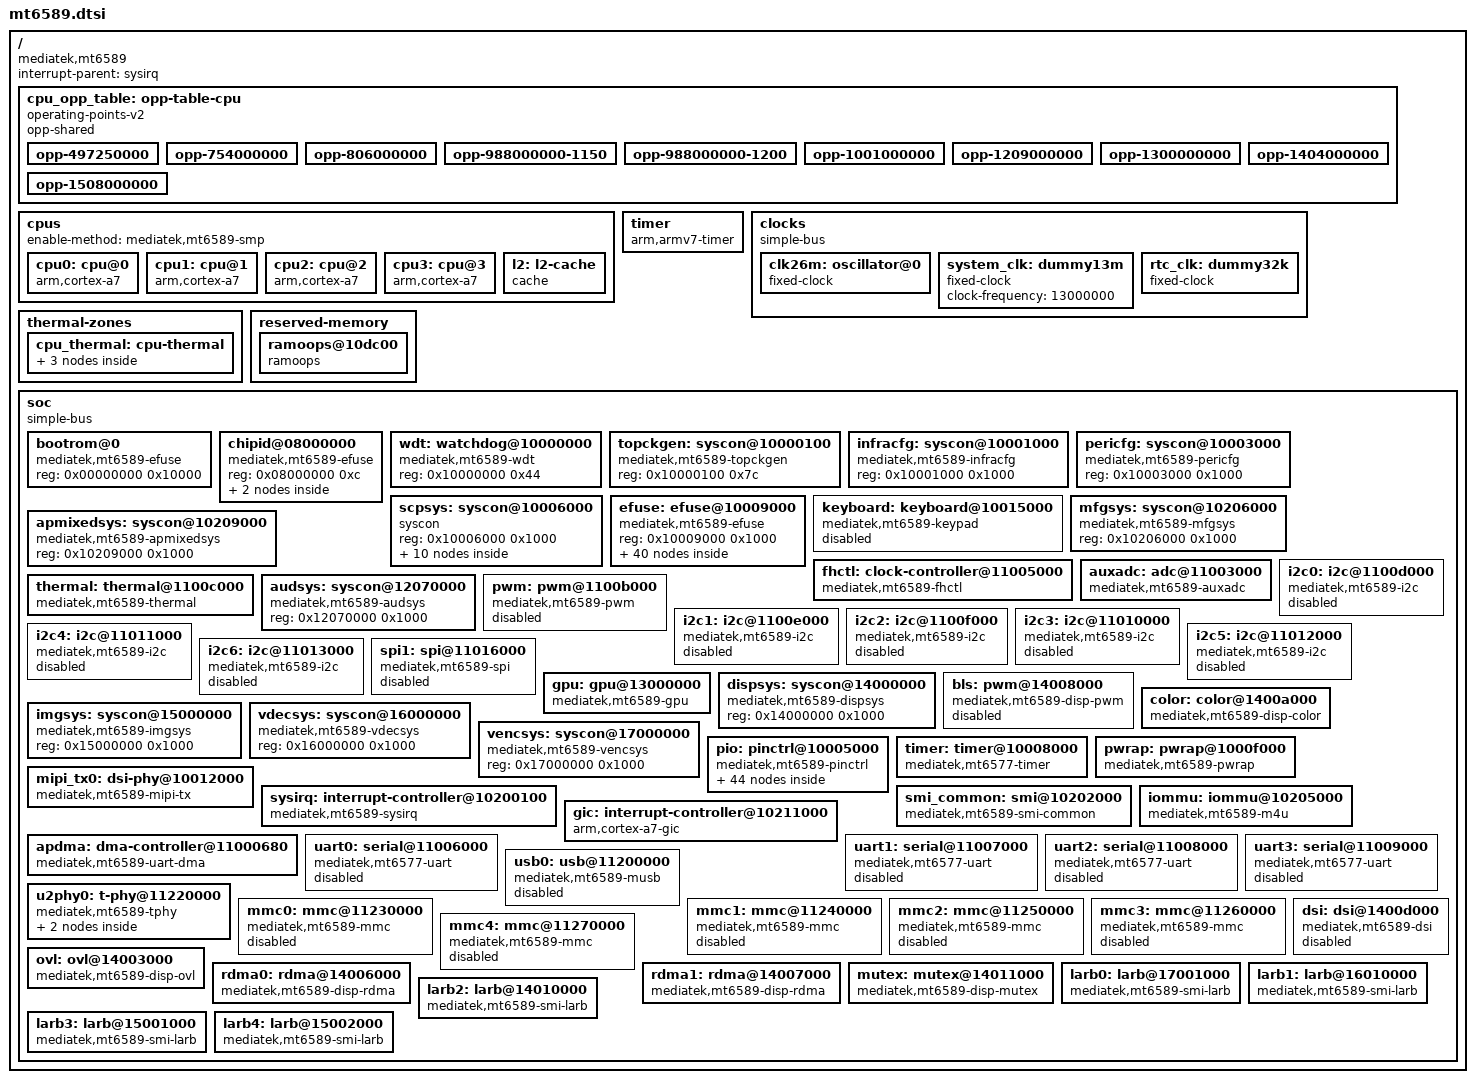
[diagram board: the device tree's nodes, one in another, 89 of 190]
// SPDX-License-Identifier: GPL-2.0+
/*
 * Copyright (c) 2014 MundoReader S.L.
 * Author: Matthias Brugger <matthias.bgg@gmail.com>
 *
*/

#include <dt-bindings/interrupt-controller/irq.h>
#include <dt-bindings/interrupt-controller/arm-gic.h>
#include <dt-bindings/clock/mediatek,mt6589-clk.h>
#include <dt-bindings/phy/phy.h>
#include <dt-bindings/reset/mt6589-resets.h>
#include <dt-bindings/pinctrl/mt6589-pinfunc.h>
#include <dt-bindings/memory/mt6589-larb-port.h>
#include <dt-bindings/power/mt6589-power.h>
#include <dt-bindings/thermal/thermal.h>

/ {
	#address-cells = <1>;
	#size-cells = <1>;
	compatible = "mediatek,mt6589";
	interrupt-parent = <&sysirq>;

	cpu_opp_table: opp-table-cpu {
		compatible = "operating-points-v2";
		opp-shared;

		/*
		 * CONFIG_MTK_FORCE_CPU_89T : 1.5 GHz : PTP 3
		 * bit 0 : free mode : ptp_free_grade
		 * bit 1 : 1.5 GHz : PTP 3 : mt6589_freqs_e1_2
		 * bit 2 : 1.4 GHz : PTP 2 : mt6589_freqs_e1_3
		 * bit 3 : 1.3 GHz : PTP 1 : mt6589_freqs_e1_4
		 * bit 4 : 1.2 GHz : PTP 0 : mt6589_freqs_e1
		 * bit 5 : 1.1 GHz : PTP 8 : mt6589_freqs_e1 (fallback)
		 * bit 6 : 1.0 GHz : PTP 9 : mt6589_freqs_e1_5
		 * bit 7 : 1.0 GHz : PTP 10: mt6589_freqs_e1 (fallback)
		 * ----- : ------- : PTP 4 : mt6589_freqs_e1_1
		 * ----- : ------- : PTP 5 : mt6589_freqs_e1_0
		 ** preloader
		 * 6, 7  : 806 MHz
		 * other : 1001MHz
		 */

		opp-497250000 {
			opp-hz = /bits/ 64 <497250000>;
			opp-microvolt = <950000>;
			opp-supported-hw = <0xff>; /* bits 0-7 */
		};

		opp-754000000 {
			opp-hz = /bits/ 64 <754000000>;
			opp-microvolt = <1050000>;
			opp-supported-hw = <0xff>;
		};

		/* TODO: can bit 6 hw run this freq with 1.15 V ? */
		opp-806000000 {
			opp-hz = /bits/ 64 <806000000>;
			opp-microvolt = <1150000>;
			opp-supported-hw = <0xff>;
		};

		opp-988000000-1150 {
			opp-hz = /bits/ 64 <988000000>;
			opp-microvolt = <1150000>;
			opp-supported-hw = <0xbf>; /* bits 0-5,7 */
		};

		opp-988000000-1200 {
			opp-hz = /bits/ 64 <988000000>;
			opp-microvolt = <1200000>;
			opp-supported-hw = <0x40>; /* bit 6 */
		};

		opp-1001000000 {
			opp-hz = /bits/ 64 <1001000000>;
			opp-microvolt = <1150000>;
			opp-supported-hw = <0x3f>; /* bits 0-5 */
		};

		opp-1209000000 {
			opp-hz = /bits/ 64 <1209000000>;
			opp-microvolt = <1200000>;
			opp-supported-hw = <0xbf>;
		};

		opp-1300000000 {
			opp-hz = /bits/ 64 <1300000000>;
			opp-microvolt = <1250000>;
			opp-supported-hw = <0x0f>; /* bits 0-3 */
		};

		opp-1404000000 {
			opp-hz = /bits/ 64 <1404000000>;
			opp-microvolt = <1250000>;
			opp-supported-hw = <0x07>; /* bits 0-2 */
		};

		opp-1508000000 {
			opp-hz = /bits/ 64 <1508000000>;
			opp-microvolt = <1250000>;
			opp-supported-hw = <0x03>; /* bits 0-1 */
		};

		/*
		 * TODO: check devinfo[10][6:4] (ptp-free@120)
		 */
		// opp-1599000000 {
		// 	opp-hz = /bits/ 64 <1599000000>;
		// 	opp-microvolt = <1250000>;
		// 	opp-supported-hw = <0x01>; /* bit 0 */
		// };

		// opp-1703000000 {
		// 	opp-hz = /bits/ 64 <1703000000>;
		// 	opp-microvolt = <1250000>;
		// 	opp-supported-hw = <0x01>; /* bit 0 */
		// };
	};

	cpus: cpus {
		#address-cells = <1>;
		#size-cells = <0>;
		enable-method = "mediatek,mt6589-smp";

		cpu0: cpu@0 {
			device_type = "cpu";
			compatible = "arm,cortex-a7";
			reg = <0x0>;

			i-cache-size = <32768>;
			i-cache-line-size = <32>;
			i-cache-sets = <512>;
			d-cache-size = <32768>;
			d-cache-line-size = <64>;
			d-cache-sets = <128>;
			next-level-cache = <&l2>;

			clocks = <&infracfg CLK_INFRA_MUX1>,
				 <&clk26m>;
			clock-names = "cpu", "intermediate";
			operating-points-v2 = <&cpu_opp_table>;
			nvmem-cells = <&chip_grade>;
			nvmem-cell-names = "speed_grade";
		};
		cpu1: cpu@1 {
			device_type = "cpu";
			compatible = "arm,cortex-a7";
			reg = <0x1>;

			i-cache-size = <32768>;
			i-cache-line-size = <32>;
			i-cache-sets = <512>;
			d-cache-size = <32768>;
			d-cache-line-size = <64>;
			d-cache-sets = <128>;
			next-level-cache = <&l2>;

			clocks = <&infracfg CLK_INFRA_MUX1>,
				 <&clk26m>;
			clock-names = "cpu", "intermediate";
			operating-points-v2 = <&cpu_opp_table>;
			nvmem-cells = <&chip_grade>;
			nvmem-cell-names = "speed_grade";
		};
		cpu2: cpu@2 {
			device_type = "cpu";
			compatible = "arm,cortex-a7";
			reg = <0x2>;

			i-cache-size = <32768>;
			i-cache-line-size = <32>;
			i-cache-sets = <512>;
			d-cache-size = <32768>;
			d-cache-line-size = <64>;
			d-cache-sets = <128>;
			next-level-cache = <&l2>;

			clocks = <&infracfg CLK_INFRA_MUX1>,
				 <&clk26m>;
			clock-names = "cpu", "intermediate";
			operating-points-v2 = <&cpu_opp_table>;
			nvmem-cells = <&chip_grade>;
			nvmem-cell-names = "speed_grade";
		};
		cpu3: cpu@3 {
			device_type = "cpu";
			compatible = "arm,cortex-a7";
			reg = <0x3>;

			i-cache-size = <32768>;
			i-cache-line-size = <32>;
			i-cache-sets = <512>;
			d-cache-size = <32768>;
			d-cache-line-size = <64>;
			d-cache-sets = <128>;
			next-level-cache = <&l2>;

			clocks = <&infracfg CLK_INFRA_MUX1>,
				 <&clk26m>;
			clock-names = "cpu", "intermediate";
			operating-points-v2 = <&cpu_opp_table>;
			nvmem-cells = <&chip_grade>;
			nvmem-cell-names = "speed_grade";
		};

		l2: l2-cache {
			compatible = "cache";
			cache-level = <2>;
			cache-size = <0x100000>;
			cache-line-size = <64>;
			cache-sets = <2048>;
			cache-unified;
		};
	};

	timer {
		compatible = "arm,armv7-timer";
		interrupt-parent = <&gic>;
		interrupts = <GIC_PPI 13 (GIC_CPU_MASK_SIMPLE(4) | IRQ_TYPE_LEVEL_LOW)>,
			     <GIC_PPI 14 (GIC_CPU_MASK_SIMPLE(4) | IRQ_TYPE_LEVEL_LOW)>,
			     <GIC_PPI 11 (GIC_CPU_MASK_SIMPLE(4) | IRQ_TYPE_LEVEL_LOW)>,
			     <GIC_PPI 10 (GIC_CPU_MASK_SIMPLE(4) | IRQ_TYPE_LEVEL_LOW)>;
		clock-frequency = <13000000>;
		arm,cpu-registers-not-fw-configured;
	};

	clocks {
		#address-cells = <1>;
		#size-cells = <1>;
		compatible = "simple-bus";
		ranges;

		clk26m: oscillator@0 {
			compatible = "fixed-clock";
			#clock-cells = <0>;
			clock-frequency = <26000000>;
			clock-output-names = "clk26m";
		};

		system_clk: dummy13m {
			compatible = "fixed-clock";
			clock-frequency = <13000000>;
			#clock-cells = <0>;
		};

		rtc_clk: dummy32k {
			compatible = "fixed-clock";
			clock-frequency = <32000>;
			clock-output-names = "rtc_clk";
			#clock-cells = <0>;
		};
	};

	thermal-zones {
		cpu_thermal: cpu-thermal {
			polling-delay-passive = <1000>;
			polling-delay = <1000>;

			thermal-sensors = <&thermal 0>;

			trips {
				cpu_alert: cpu-alert {
					temperature = <85000>;
					hysteresis = <2000>;
					type = "hot";
				};

				cpu_crit: cpu-crit {
					temperature = <115000>;
					hysteresis = <2000>;
					type = "critical";
				};
			};
		};
	};

	reserved-memory {
		#address-cells = <1>;
		#size-cells = <1>;
		ranges;

		/* part of on-chip sram */
		ramoops@10dc00 {
			compatible = "ramoops";
			reg = <0x0010dc00 0x1c00>;
			record-size = <0x400>;
			console-size = <0x1000>;
		};
	};

	soc {
		#address-cells = <1>;
		#size-cells = <1>;
		compatible = "simple-bus";
		ranges;

		bootrom@0 {
			compatible = "mediatek,mt6589-efuse",
				     "mediatek,mt6572-efuse";
			reg = <0x00000000 0x10000>;
			#address-cells = <1>;
			#size-cells = <1>;
		};

		/*
		 * 0x08000000  CHIP_ID   0x8a006583  Main(0x6583) / Sub(0x8a00)
		 * 0x08000004  CHIP_VER  0x0000ca00  HW ID(0xca00) / SW ID(0x0000)
		 */
		chipid@08000000 {
			compatible = "mediatek,mt6589-efuse",
				     "mediatek,mt6572-efuse";
			reg = <0x08000000 0xc>;
			#address-cells = <1>;
			#size-cells = <1>;

			chip-id@0 {
				reg = <0x0 0x4>;
			};

			chip-ver@ {
				reg = <0x4 0x4>;
			};
		};

		wdt: watchdog@10000000 {
			compatible = "mediatek,mt6589-wdt";
			reg = <0x10000000 0x44>;
			#reset-cells = <1>;
		};

		topckgen: syscon@10000100 {
			compatible = "mediatek,mt6589-topckgen", "syscon";
			reg = <0x10000100 0x7c>;
			#clock-cells = <1>;
		};

		infracfg: syscon@10001000 {
			compatible = "mediatek,mt6589-infracfg", "syscon";
			reg = <0x10001000 0x1000>;
			#clock-cells = <1>;
			#reset-cells = <1>;
		};

		pericfg: syscon@10003000 {
			compatible = "mediatek,mt6589-pericfg", "syscon";
			reg = <0x10003000 0x1000>;
			#clock-cells = <1>;
			#reset-cells = <1>;
		};

		scpsys: syscon@10006000 {
			compatible = "syscon", "simple-mfd";
			reg = <0x10006000 0x1000>;
			#power-domain-cells = <1>;

			spm: power-controller {
				compatible = "mediatek,mt6589-power-controller";
				#address-cells = <1>;
				#size-cells = <0>;
				#power-domain-cells = <1>;

				power-domain@MT6589_POWER_DOMAIN_MD1 {
					reg = <MT6589_POWER_DOMAIN_MD1>;
					#power-domain-cells = <0>;
					mediatek,infracfg = <&infracfg>;
				};

				power-domain@MT6589_POWER_DOMAIN_MD2 {
					reg = <MT6589_POWER_DOMAIN_MD2>;
					#power-domain-cells = <0>;
					mediatek,infracfg = <&infracfg>;
				};

				power-domain@MT6589_POWER_DOMAIN_DPY {
					reg = <MT6589_POWER_DOMAIN_DPY>;
					#power-domain-cells = <0>;
				};

				power-domain@MT6589_POWER_DOMAIN_DIS {
					reg = <MT6589_POWER_DOMAIN_DIS>;
					clocks = <&topckgen CLK_TOP_MUX_DISP>;
					clock-names = "disp";
					#power-domain-cells = <0>;
				};

				power-domain@MT6589_POWER_DOMAIN_MFG {
					reg = <MT6589_POWER_DOMAIN_MFG>;
					clocks = <&topckgen CLK_TOP_MUX_MFG>,
						 <&topckgen CLK_TOP_MUX_SMI_MFG_AS>;
					clock-names = "mfg", "mfg_as";
					#power-domain-cells = <0>;
					mediatek,infracfg = <&infracfg>;
				};

				power-domain@MT6589_POWER_DOMAIN_ISP {
					reg = <MT6589_POWER_DOMAIN_ISP>;
					#power-domain-cells = <0>;
				};

				power-domain@MT6589_POWER_DOMAIN_IFR {
					reg = <MT6589_POWER_DOMAIN_IFR>;
					#power-domain-cells = <0>;
				};

				power-domain@MT6589_POWER_DOMAIN_VEN {
					reg = <MT6589_POWER_DOMAIN_VEN>;
					clocks = <&topckgen CLK_TOP_MUX_VENC>;
					clock-names = "venc";
					#power-domain-cells = <0>;
				};

				power-domain@MT6589_POWER_DOMAIN_VDE {
					reg = <MT6589_POWER_DOMAIN_VDE>;
					clocks = <&topckgen CLK_TOP_MUX_VDEC>;
					clock-names = "vdec";
					#power-domain-cells = <0>;
				};
			};
		};

		efuse: efuse@10009000 {
			compatible = "mediatek,mt6589-efuse",
				     "mediatek,mt6572-efuse";
			reg = <0x10009000 0x1000>;
			#address-cells = <1>;
			#size-cells = <1>;

			cell@20 {
				reg = <0x20 0x4>;
			};

			cell@30 {
				reg = <0x30 0x4>;
			};

			cell@38 {
				reg = <0x38 0x4>;
			};

			/*
			 * bit[2:0]  chip_grade
			 *
			 * bit[27:24]  core_count_flag
			 *   0x0   : 4 cores
			 *   others: 2 cores
			 */
			chip_grade: chip-grade@40 {
				reg = <0x40 0x4>;
				bits = <0 3>;
			};

			core_count_flag: core-count@40 {
				reg = <0x40 0x4>;
				bits = <24 4>;
			};

			cell@40 {
				reg = <0x40 0x4>;
			};

			cell@44 {
				reg = <0x44 0x4>;
			};

			cell@48 {
				reg = <0x48 0x4>;
			};

			/*
			 * Secure boot flag
			 *   bit[1]  sbc_enabled  Secure Boot Check
			 *   bit[2]  daa_enabled  Device Authentication Auth
			 *   bit[3]  sla_enabled  Secure Lock Auth
			 */
			sbc_enabled: sbc@60 {
				reg = <0x60 0x4>;
				bits = <1 1>;
			};

			daa_enabled: daa@60 {
				reg = <0x60 0x4>;
				bits = <2 1>;
			};

			sla_enabled: sla@60 {
				reg = <0x60 0x4>;
				bits = <3 1>;
			};

			thermal_cal_data: thermal-cal@100 {
				reg = <0x100 0xc>;
			};

			dis_3g: dis-3g@100 {
				reg = <0x100 0x4>;
				bits = <24 1>;
			};

			ptp_free_grade: ptp-free@120 {
				reg = <0x120 0x4>;
				bits = <4 3>;
			};

			cell@120 {
				reg = <0x120 0x4>;
			};

			cell@130 {
				reg = <0x130 0x4>;
			};

			usb_serial_lo: usb-serial-lo@140 {
				reg = <0x140 0x4>;
			};

			usb_serial_hi: usb-serial-hi@144 {
				reg = <0x144 0x4>;
			};

			/*
			 * bit[15:13]  RG_USB20_TERM_VREF_SEL offset (3bit)
			 * bit[12:10]  RG_USB20_CLKREF_REF offset (3bit)
			 * bit[9:7]    RG_USB20_VRT_VREF_SEL offset (3bit)
			 */
			usb_term_vref: usb-term-vref@170 {
				reg = <0x170 0x2>;
				bits = <7 3>;
			};

			usb_clkref: usb-clkref@170 {
				reg = <0x170 0x2>;
				bits = <10 3>;
			};

			usb_vrt_vref: usb-vrt-vref@170 {
				reg = <0x170 0x2>;
				bits = <13 3>;
			};

			cell@170 {
				reg = <0x170 0x4>;
			};

			cell@174 {
				reg = <0x174 0x4>;
			};

			ptp_od_data: ptp-od@178 {
				reg = <0x178 0x10>;
			};

			ptp_initen: ptp-initen@178 {
				reg = <0x178 0x4>;
				bits = <0 1>;
			};

			ptp_monen: ptp-monen@178 {
				reg = <0x178 0x4>;
				bits = <1 1>;
			};

			ptp_mdes: ptp-mdes@178 {
				reg = <0x178 0x4>;
				bits = <8 8>;
			};

			ptp_bdes: ptp-bdes@178 {
				reg = <0x178 0x4>;
				bits = <16 8>;
			};

			ptp_dcmdet: ptp-dcmdet@178 {
				reg = <0x178 0x4>;
				bits = <24 8>;
			};

			ptp_dcconfig: ptp-dcconfig@17c {
				reg = <0x17c 0x4>;
				bits = <0 24>;
			};

			ptp_dcbdet: ptp-dcbdet@17c {
				reg = <0x17c 0x4>;
				bits = <24 8>;
			};

			ptp_ageconfig: ptp-ageconfig@180 {
				reg = <0x180 0x4>;
				bits = <0 24>;
			};

			ptp_agem: ptp-agem@180 {
				reg = <0x180 0x4>;
				bits = <24 8>;
			};

			ptp_dvtfixed: ptp-dvtfixed@184 {
				reg = <0x184 0x4>;
				bits = <8 8>;
			};

			ptp_mtdes: ptp-mtdes@184 {
				reg = <0x184 0x4>;
				bits = <16 8>;
			};

			ptp_vco: ptp-vco@184 {
				reg = <0x184 0x4>;
				bits = <24 8>;
			};

			cell@178 {
				reg = <0x178 0x4>;
			};

			cell@17c {
				reg = <0x17c 0x4>;
			};

			cell@180 {
				reg = <0x180 0x4>;
			};

			cell@184 {
				reg = <0x184 0x4>;
			};
		};

		keyboard: keyboard@10015000 {
			compatible = "mediatek,mt6589-keypad",
				     "mediatek,mt6779-keypad";
			reg = <0x10015000 0x1000>;
			interrupts = <GIC_SPI 129 IRQ_TYPE_EDGE_FALLING>;
			clocks = <&infracfg CLK_INFRA_KP>;
			clock-names = "kpd";
			status = "disabled";
		};

		mfgsys: syscon@10206000 {
			compatible = "mediatek,mt6589-mfgsys", "syscon";
			reg = <0x10206000 0x1000>;
			#clock-cells = <1>;
		};

		apmixedsys: syscon@10209000 {
			compatible = "mediatek,mt6589-apmixedsys", "syscon";
			reg = <0x10209000 0x1000>;
			#clock-cells = <1>;
		};

		fhctl: clock-controller@11005000 {
			compatible = "mediatek,mt6589-fhctl";
			reg = <0x11005000 0x100>;
			clocks = <&apmixedsys CLK_APMIXED_ARMPLL>,
				 <&apmixedsys CLK_APMIXED_MAINPLL>,
				 <&apmixedsys CLK_APMIXED_MSDCPLL>,
				 <&apmixedsys CLK_APMIXED_TVDPLL>,
				 <&apmixedsys CLK_APMIXED_LVDSPLL>;
			mediatek,hopping-ssc-percent = <0>, <0>, <3>, <0>, <0>;
		};

		auxadc: adc@11003000 {
			compatible = "mediatek,mt6589-auxadc";
			reg = <0x11003000 0x1000>;
			clocks = <&pericfg CLK_PERI1_AUXADC>;
			clock-names = "main";
			#io-channel-cells = <1>;
		};

		thermal: thermal@1100c000 {
			compatible = "mediatek,mt6589-thermal";
			reg = <0x1100c000 0x1000>;
			interrupts = <GIC_SPI 38 IRQ_TYPE_LEVEL_LOW>;
			clocks = <&pericfg CLK_PERI0_THERM>,
				 <&pericfg CLK_PERI1_AUXADC>;
			clock-names = "therm", "auxadc";
			mediatek,auxadc = <&auxadc>;
			mediatek,apmixedsys = <&apmixedsys>;
			nvmem-cells = <&thermal_cal_data>;
			nvmem-cell-names = "calibration-data";
			#thermal-sensor-cells = <1>;
		};

		audsys: syscon@12070000 {
			compatible = "mediatek,mt6589-audsys", "syscon";
			reg = <0x12070000 0x1000>;
			#clock-cells = <1>;
		};

		pwm: pwm@1100b000 {
			compatible = "mediatek,mt6589-pwm",
				     "mediatek,mt6795-pwm";
			reg = <0x1100b000 0x1000>;
			#pwm-cells = <2>;
			interrupts = <GIC_SPI 37 IRQ_TYPE_LEVEL_LOW>;
			clocks = <&pericfg CLK_PERI0_PWM>,
				 <&pericfg CLK_PERI0_PWM>,
				 <&pericfg CLK_PERI0_PWM1>,
				 <&pericfg CLK_PERI0_PWM2>,
				 <&pericfg CLK_PERI0_PWM3>,
				 <&pericfg CLK_PERI0_PWM4>,
				 <&pericfg CLK_PERI0_PWM5>,
				 <&pericfg CLK_PERI0_PWM6>,
				 <&pericfg CLK_PERI0_PWM7>;
			clock-names = "top", "main", "pwm1", "pwm2", "pwm3",
				      "pwm4", "pwm5", "pwm6", "pwm7";
			status = "disabled";
		};

		i2c0: i2c@1100d000 {
			compatible = "mediatek,mt6589-i2c";
			reg = <0x1100d000 0x1000>,
			      <0x11000300 0x80>;
			interrupts = <GIC_SPI 44 IRQ_TYPE_LEVEL_LOW>;
			clocks = <&pericfg CLK_PERI0_I2C0>,
				 <&pericfg CLK_PERI0_APDMA>;
			clock-names = "main", "dma";
			clock-div = <16>;
			status = "disabled";
			#address-cells = <1>;
			#size-cells = <0>;
		};

		i2c1: i2c@1100e000 {
			compatible = "mediatek,mt6589-i2c";
			reg = <0x1100e000 0x1000>,
			      <0x11000380 0x80>;
			interrupts = <GIC_SPI 45 IRQ_TYPE_LEVEL_LOW>;
			clocks = <&pericfg CLK_PERI0_I2C1>,
				 <&pericfg CLK_PERI0_APDMA>;
			clock-names = "main", "dma";
			clock-div = <16>;
			status = "disabled";
			#address-cells = <1>;
			#size-cells = <0>;
		};

		i2c2: i2c@1100f000 {
			compatible = "mediatek,mt6589-i2c";
			reg = <0x1100f000 0x1000>,
			      <0x11000400 0x80>;
			interrupts = <GIC_SPI 46 IRQ_TYPE_LEVEL_LOW>;
			clocks = <&pericfg CLK_PERI0_I2C2>,
				 <&pericfg CLK_PERI0_APDMA>;
			clock-names = "main", "dma";
			clock-div = <16>;
			status = "disabled";
			#address-cells = <1>;
			#size-cells = <0>;
		};

		i2c3: i2c@11010000 {
			compatible = "mediatek,mt6589-i2c";
			reg = <0x11010000 0x1000>,
			      <0x11000480 0x80>;
			interrupts = <GIC_SPI 47 IRQ_TYPE_LEVEL_LOW>;
			clocks = <&pericfg CLK_PERI0_I2C3>,
				 <&pericfg CLK_PERI0_APDMA>;
			clock-names = "main", "dma";
			clock-div = <16>;
			status = "disabled";
			#address-cells = <1>;
			#size-cells = <0>;
		};

		i2c4: i2c@11011000 {
			compatible = "mediatek,mt6589-i2c";
			reg = <0x11011000 0x1000>,
			      <0x11000500 0x80>;
			interrupts = <GIC_SPI 48 IRQ_TYPE_LEVEL_LOW>;
			clock-names = "main", "pmic", "dma";
			clock-div = <1>;
			mediatek,have-pmic;
			status = "disabled";
			#address-cells = <1>;
			#size-cells = <0>;
		};

		i2c5: i2c@11012000 {
			compatible = "mediatek,mt6589-i2c";
			reg = <0x11012000 0x1000>,
			      <0x11000580 0x80>;
			interrupts = <GIC_SPI 49 IRQ_TYPE_LEVEL_LOW>;
			clock-names = "main", "pmic", "dma";
			clock-div = <1>;
			mediatek,have-pmic;
			status = "disabled";
			#address-cells = <1>;
			#size-cells = <0>;
		};

		i2c6: i2c@11013000 {
			compatible = "mediatek,mt6589-i2c";
			reg = <0x11013000 0x1000>,
			      <0x11000600 0x80>;
			interrupts = <GIC_SPI 50 IRQ_TYPE_LEVEL_LOW>;
			clock-names = "main", "pmic", "dma";
			clock-div = <1>;
			mediatek,have-pmic;
			status = "disabled";
			#address-cells = <1>;
			#size-cells = <0>;
		};

		spi1: spi@11016000 {
			compatible = "mediatek,mt6589-spi";
			#address-cells = <1>;
			#size-cells = <0>;
			reg = <0x11016000 0x1000>;
			interrupts = <GIC_SPI 78 IRQ_TYPE_LEVEL_LOW>;
			clocks = <&clk26m>, /* FIXME */
				 <&topckgen CLK_TOP_MUX_SPI>,
				 <&pericfg CLK_PERI1_SPI1>;
			clock-names = "parent-clk", "sel-clk", "spi-clk";
			status = "disabled";
		};

		gpu: gpu@13000000 {
			compatible = "mediatek,mt6589-gpu", "img,powervr-sgx544";
			reg = <0x13000000 0x10000>;
			interrupts = <GIC_SPI 188 IRQ_TYPE_LEVEL_LOW>;
			clocks = <&mfgsys CLK_MFG_G3D>,
				 <&mfgsys CLK_MFG_MEM>,
				 <&mfgsys CLK_MFG_AXI>;
			clock-names = "core", "mem", "sys";
		};

		dispsys: syscon@14000000 {
			compatible = "mediatek,mt6589-dispsys", "syscon";
			reg = <0x14000000 0x1000>;
			#clock-cells = <1>;
			#reset-cells = <1>;
		};

		bls: pwm@14008000 {
			compatible = "mediatek,mt6589-disp-pwm";
			reg = <0x14008000 0x1000>;
			#pwm-cells = <2>;
			clocks = <&dispsys CLK_DISP0_BLS>;
			clock-names = "main";
			power-domains = <&spm MT6589_POWER_DOMAIN_DIS>; /* maybe */
			status = "disabled";
		};

		color: color@1400a000 {
			compatible = "mediatek,mt6589-disp-color";
			reg = <0x1400a000 0x1000>;
			interrupts = <GIC_SPI 169 IRQ_TYPE_LEVEL_LOW>;
			clocks = <&dispsys CLK_DISP0_COLOR>;
		};

		imgsys: syscon@15000000 {
			compatible = "mediatek,mt6589-imgsys", "syscon";
			reg = <0x15000000 0x1000>;
			#clock-cells = <1>;
		};

		vdecsys: syscon@16000000 {
			compatible = "mediatek,mt6589-vdecsys", "syscon";
			reg = <0x16000000 0x1000>;
			#clock-cells = <1>;
		};

		vencsys: syscon@17000000 {
			compatible = "mediatek,mt6589-vencsys", "syscon";
			reg = <0x17000000 0x1000>;
			#clock-cells = <1>;
		};

		pio: pinctrl@10005000 {
			compatible = "mediatek,mt6589-pinctrl";
			reg = <0x10005000 0x1000>,
			      <0x1020c000 0x1000>,
			      <0x1000b000 0x1000>;
			reg-names = "gpio", "gpio1", "eint";
			gpio-controller;
			#gpio-cells = <2>;
			gpio-ranges = <&pio 0 0 232>;
			interrupt-controller;
			interrupt-parent = <&gic>;
			#interrupt-cells = <2>;
			interrupts = <GIC_SPI 116 IRQ_TYPE_LEVEL_HIGH>,
				     <GIC_SPI 117 IRQ_TYPE_LEVEL_HIGH>,
				     <GIC_SPI 118 IRQ_TYPE_LEVEL_HIGH>;
		};

		timer: timer@10008000 {
			compatible = "mediatek,mt6577-timer";
			reg = <0x10008000 0x80>;
			interrupts = <GIC_SPI 113 IRQ_TYPE_LEVEL_LOW>;
			clocks = <&system_clk>, <&rtc_clk>;
			clock-names = "system-clk", "rtc-clk";
		};

		pwrap: pwrap@1000f000 {
			compatible = "mediatek,mt6589-pwrap";
			reg = <0x1000f000 0x1000>,
			      <0x11017000 0x1000>;
			reg-names = "pwrap", "pwrap-bridge";
			interrupts = <GIC_SPI 128 IRQ_TYPE_LEVEL_HIGH>;
			clocks = <&infracfg CLK_INFRA_PMICSPI>,
				 <&infracfg CLK_INFRA_PMICWRAP>;
			clock-names = "spi", "wrap";
			resets = <&infracfg MT6589_INFRA_PMIC_WRAP_RST>,
				 <&pericfg MT6589_PERI_PWRAP_BRIDGE_SW_RST>;
			reset-names = "pwrap", "pwrap-bridge";
		};

		mipi_tx0: dsi-phy@10012000 {
			compatible = "mediatek,mt6589-mipi-tx";
			reg = <0x10012000 0x90>;
			clocks = <&clk26m>;
			/* <&dispsys CLK_DISP1_DSI_DIGITAL_LANE> ? */
			clock-output-names = "mipi_tx0_pll";
			#clock-cells = <0>;
			#phy-cells = <0>;
		};

		sysirq: interrupt-controller@10200100 {
			compatible = "mediatek,mt6589-sysirq",
				     "mediatek,mt6577-sysirq";
			interrupt-controller;
			#interrupt-cells = <3>;
			interrupt-parent = <&gic>;
			reg = <0x10200100 0x1c>;
		};

		smi_common: smi@10202000 {
			compatible = "mediatek,mt6589-smi-common";
			reg = <0x10202000 0x1000>, <0x1000e000 0x1000>;
			clocks = <&infracfg CLK_INFRA_SMI>,
				 <&infracfg CLK_INFRA_SMI>;
			clock-names = "apb", "smi";
			power-domains = <&spm MT6589_POWER_DOMAIN_DIS>; /* maybe */
		};

		iommu: iommu@10205000 {
			compatible = "mediatek,mt6589-m4u";
			reg = <0x10205000 0x100>,
			      <0x10205200 0x600>,
			      <0x10205800 0x600>,
			      <0x10205100 0x100>;
			reg-names = "global", "m4u0", "m4u1", "l2cache";
			interrupts = <GIC_SPI 105 IRQ_TYPE_LEVEL_LOW>,
				     <GIC_SPI 106 IRQ_TYPE_LEVEL_LOW>,
				     <GIC_SPI 107 IRQ_TYPE_LEVEL_LOW>,
				     <GIC_SPI 108 IRQ_TYPE_LEVEL_LOW>;
			interrupt-names = "m4u0", "m4u1", "m4ul2", "m4ul2-sec";
			/* m4ul2 and m4ul2-sec are not used by driver */
			clocks = <&infracfg CLK_INFRA_M4U>;
			clock-names = "bclk";
			mediatek,larbs = <&larb0>, <&larb1>, <&larb2>,
					 <&larb3>, <&larb4>;
			#iommu-cells = <1>;
			power-domains = <&spm MT6589_POWER_DOMAIN_DIS>; /* maybe */
		};

		gic: interrupt-controller@10211000 {
			compatible = "arm,cortex-a7-gic";
			interrupt-controller;
			#interrupt-cells = <3>;
			interrupt-parent = <&gic>;
			reg = <0x10211000 0x1000>,
			      <0x10212000 0x2000>,
			      <0x10214000 0x2000>,
			      <0x10216000 0x2000>;
		};

		apdma: dma-controller@11000680 {
			compatible = "mediatek,mt6589-uart-dma",
				     "mediatek,mt6577-uart-dma";
			reg = <0x11000680 0x54>,
			      <0x11000700 0x54>,
			      <0x11000780 0x54>,
			      <0x11000800 0x54>,
			      <0x11000880 0x54>,
			      <0x11000900 0x54>;
			interrupts = <GIC_SPI 65 IRQ_TYPE_LEVEL_HIGH>,
				     <GIC_SPI 66 IRQ_TYPE_LEVEL_HIGH>,
				     <GIC_SPI 67 IRQ_TYPE_LEVEL_HIGH>,
				     <GIC_SPI 68 IRQ_TYPE_LEVEL_HIGH>,
				     <GIC_SPI 69 IRQ_TYPE_LEVEL_HIGH>,
				     <GIC_SPI 70 IRQ_TYPE_LEVEL_HIGH>;
			dma-requests = <6>;
			clocks = <&pericfg CLK_PERI0_APDMA>;
			clock-names = "apdma";
			#dma-cells = <1>;
		};

		uart0: serial@11006000 {
			compatible = "mediatek,mt6577-uart";
			reg = <0x11006000 0x400>;
			interrupts = <GIC_SPI 51 IRQ_TYPE_LEVEL_LOW>;
			clocks = <&pericfg CLK_PERI_MUX_UART0>, <&pericfg CLK_PERI0_UART0>;
			clock-names = "baud", "bus";
			dmas = <&apdma 0>, <&apdma 1>;
			dma-names = "tx", "rx";
			status = "disabled";
		};

		uart1: serial@11007000 {
			compatible = "mediatek,mt6577-uart";
			reg = <0x11007000 0x400>;
			interrupts = <GIC_SPI 52 IRQ_TYPE_LEVEL_LOW>;
			clocks = <&pericfg CLK_PERI_MUX_UART1>, <&pericfg CLK_PERI0_UART1>;
			clock-names = "baud", "bus";
			dmas = <&apdma 2>, <&apdma 3>;
			dma-names = "tx", "rx";
			status = "disabled";
		};

		uart2: serial@11008000 {
			compatible = "mediatek,mt6577-uart";
			reg = <0x11008000 0x400>;
			interrupts = <GIC_SPI 53 IRQ_TYPE_LEVEL_LOW>;
			clocks = <&pericfg CLK_PERI_MUX_UART2>, <&pericfg CLK_PERI0_UART2>;
			clock-names = "baud", "bus";
			dmas = <&apdma 4>, <&apdma 5>;
			dma-names = "tx", "rx";
			status = "disabled";
		};

		uart3: serial@11009000 {
			/* NOTE: MT6589 does not have DMA for UART3 */
			compatible = "mediatek,mt6577-uart";
			reg = <0x11009000 0x400>;
			interrupts = <GIC_SPI 54 IRQ_TYPE_LEVEL_LOW>;
			clocks = <&pericfg CLK_PERI_MUX_UART3>, <&pericfg CLK_PERI0_UART3>;
			clock-names = "baud", "bus";
			status = "disabled";
		};

		/* USB 2.0 */
		usb0: usb@11200000 {
			compatible = "mediatek,mt6589-musb",
				     "mediatek,mtk-musb";
			reg = <0x11200000 0x1000>;
			interrupts = <GIC_SPI 32 IRQ_TYPE_LEVEL_LOW>;
			interrupt-names = "mc";
			phys = <&usb_port0 PHY_TYPE_USB2>;
			dr_mode = "otg";
			clocks = <&pericfg CLK_PERI0_USB0>,
				 <&pericfg CLK_PERI0_USB0>,
				 <&apmixedsys CLK_APMIXED_UNIVPLL_USB_48M>;
			clock-names = "main", "mcu", "univpll";
			resets = <&pericfg MT6589_PERI_USB_SW_RST>;
			reset-names = "hrst";
			status = "disabled";
		};

		u2phy0: t-phy@11220000 {
			compatible = "mediatek,mt6589-tphy";
			reg = <0x11220000 0x0800>,
			      <0x11220f00 0x0100>;
			reg-names = "sif", "legacy-fm";
			mediatek,src-ref-clk-mhz = <48>;
			mediatek,src-coef = <22>;
			ranges;
			status = "okay";
			#address-cells = <1>;
			#size-cells = <1>;

			/* USB 2.0 */
			usb_port0: usb-phy@11220800 {
				reg = <0x11220800 0x0100>;
				clocks = <&apmixedsys CLK_APMIXED_UNIVPLL_USB_48M>;
				clock-names = "ref";
				#phy-cells = <1>;
				status = "okay";
			};

			/* USB 1.1 */
			usb_port1: usb-phy@11220900 {
				reg = <0x11220900 0x0100>;
				clocks = <&apmixedsys CLK_APMIXED_UNIVPLL_USB_48M>;
				clock-names = "ref";
				#phy-cells = <1>;
				status = "disabled";
			};
		};

		mmc0: mmc@11230000 {
			compatible = "mediatek,mt6589-mmc",
				     "mediatek,mt8135-mmc";
			reg = <0x11230000 0x1000>;
			interrupts = <GIC_SPI 39 IRQ_TYPE_LEVEL_LOW>;
			clocks = <&pericfg CLK_PERI0_MSDC0>,
				 <&topckgen CLK_TOP_MUX_MSDC0>;
			clock-names = "source", "hclk";
			status = "disabled";
		};

		mmc1: mmc@11240000 {
			compatible = "mediatek,mt6589-mmc",
				     "mediatek,mt8135-mmc";
			reg = <0x11240000 0x1000>;
			interrupts = <GIC_SPI 40 IRQ_TYPE_LEVEL_LOW>;
			clocks = <&pericfg CLK_PERI0_MSDC1>,
				 <&topckgen CLK_TOP_MUX_MSDC1>;
			clock-names = "source", "hclk";
			status = "disabled";
		};

		mmc2: mmc@11250000 {
			compatible = "mediatek,mt6589-mmc",
				     "mediatek,mt8135-mmc";
			reg = <0x11250000 0x1000>;
			interrupts = <GIC_SPI 41 IRQ_TYPE_LEVEL_LOW>;
			clocks = <&pericfg CLK_PERI0_MSDC2>,
				 <&topckgen CLK_TOP_MUX_MSDC2>;
			clock-names = "source", "hclk";
			status = "disabled";
		};

		mmc3: mmc@11260000 {
			compatible = "mediatek,mt6589-mmc",
				     "mediatek,mt8135-mmc";
			reg = <0x11260000 0x1000>;
			interrupts = <GIC_SPI 42 IRQ_TYPE_LEVEL_LOW>;
			clocks = <&pericfg CLK_PERI0_MSDC3>,
				 <&topckgen CLK_TOP_MUX_MSDC3>;
			clock-names = "source", "hclk";
			status = "disabled";
		};

		mmc4: mmc@11270000 {
			compatible = "mediatek,mt6589-mmc",
				     "mediatek,mt8135-mmc";
			reg = <0x11270000 0x1000>;
			interrupts = <GIC_SPI 83 IRQ_TYPE_LEVEL_LOW>;
			clocks = <&pericfg CLK_PERI0_MSDC4>,
				 <&topckgen CLK_TOP_MUX_MSDC4>;
			clock-names = "source", "hclk";
			status = "disabled";
		};

		ovl: ovl@14003000 {
			compatible = "mediatek,mt6589-disp-ovl";
			reg = <0x14003000 0x1000>;
			interrupts = <GIC_SPI 163 IRQ_TYPE_LEVEL_LOW>;
			clocks = <&dispsys CLK_DISP0_OVL_ENGINE>,
				 <&dispsys CLK_DISP0_OVL_SMI>;
			iommus = <&iommu MT6589_M4U_PORT_OVL_CH0>,
				 <&iommu MT6589_M4U_PORT_OVL_CH1>,
				 <&iommu MT6589_M4U_PORT_OVL_CH2>,
				 <&iommu MT6589_M4U_PORT_OVL_CH3>;
			power-domains = <&spm MT6589_POWER_DOMAIN_DIS>; /* maybe */
		};

		rdma0: rdma@14006000 {
			compatible = "mediatek,mt6589-disp-rdma";
			reg = <0x14006000 0x1000>;
			interrupts = <GIC_SPI 166 IRQ_TYPE_LEVEL_LOW>;
			clocks = <&dispsys CLK_DISP0_RDMA0_ENGINE>,
				 <&dispsys CLK_DISP0_RDMA0_SMI>,
				 <&dispsys CLK_DISP0_RDMA0_OUTPUT>;
			iommus = <&iommu MT6589_M4U_PORT_RDMA0>;
			power-domains = <&spm MT6589_POWER_DOMAIN_DIS>; /* maybe */
		};

		rdma1: rdma@14007000 {
			compatible = "mediatek,mt6589-disp-rdma";
			reg = <0x14007000 0x1000>;
			interrupts = <GIC_SPI 167 IRQ_TYPE_LEVEL_LOW>;
			clocks = <&dispsys CLK_DISP0_RDMA1_ENGINE>,
				 <&dispsys CLK_DISP0_RDMA1_SMI>,
				 <&dispsys CLK_DISP0_RDMA1_OUTPUT>;
			iommus = <&iommu MT6589_M4U_PORT_RDMA1>;
			power-domains = <&spm MT6589_POWER_DOMAIN_DIS>; /* maybe */
		};

		mutex: mutex@14011000 {
			compatible = "mediatek,mt6589-disp-mutex";
			reg = <0x14011000 0x1000>;
			interrupts = <GIC_SPI 160 IRQ_TYPE_LEVEL_LOW>;
			/* not found in clock list */
			clocks = <&clk26m>;
			power-domains = <&spm MT6589_POWER_DOMAIN_DIS>; /* maybe */
		};

		dsi: dsi@1400d000 {
			compatible = "mediatek,mt6589-dsi";
			reg = <0x1400d000 0x1000>;
			interrupts = <GIC_SPI 172 IRQ_TYPE_LEVEL_LOW>;
			clocks = <&dispsys CLK_DISP1_DSI_ENGINE>,
				 <&dispsys CLK_DISP1_DSI_DIGITAL>,
				 <&mipi_tx0>;
			clock-names = "engine", "digital", "hs";
			phys = <&mipi_tx0>;
			phy-names = "dphy";
			power-domains = <&spm MT6589_POWER_DOMAIN_DIS>; /* maybe */
			status = "disabled";
		};

		larb0: larb@17001000 {
			compatible = "mediatek,mt6589-smi-larb";
			reg = <0x17001000 0x1000>;
			mediatek,smi = <&smi_common>;
			mediatek,larb-id = <0>;
			clocks = <&vencsys CLK_VENC_VEN>,
				 <&vencsys CLK_VENC_VEN>;
			clock-names = "apb", "smi";
			power-domains = <&spm MT6589_POWER_DOMAIN_DIS>; /* maybe */
		};

		larb1: larb@16010000 {
			compatible = "mediatek,mt6589-smi-larb";
			reg = <0x16010000 0x1000>;
			mediatek,smi = <&smi_common>;
			mediatek,larb-id = <1>;
			clocks = <&vdecsys CLK_VDEC0_VDE>,
				 <&vdecsys CLK_VDEC1_SMI>;
			clock-names = "apb", "smi";
			power-domains = <&spm MT6589_POWER_DOMAIN_DIS>; /* maybe */
		};

		larb2: larb@14010000 {
			compatible = "mediatek,mt6589-smi-larb";
			reg = <0x14010000 0x1000>;
			mediatek,smi = <&smi_common>;
			mediatek,larb-id = <2>;
			clocks = <&dispsys CLK_DISP0_LARB2_SMI>,
				 <&dispsys CLK_DISP0_LARB2_SMI>;
			clock-names = "apb", "smi";
			power-domains = <&spm MT6589_POWER_DOMAIN_DIS>; /* maybe */
		};

		larb3: larb@15001000 {
			compatible = "mediatek,mt6589-smi-larb";
			reg = <0x15001000 0x1000>;
			mediatek,smi = <&smi_common>;
			mediatek,larb-id = <3>;
			clocks = <&imgsys CLK_IMAGE_LARB3_SMI>,
				 <&imgsys CLK_IMAGE_LARB3_SMI>;
			clock-names = "apb", "smi";
			power-domains = <&spm MT6589_POWER_DOMAIN_DIS>; /* maybe */
		};

		larb4: larb@15002000 {
			compatible = "mediatek,mt6589-smi-larb";
			reg = <0x15002000 0x1000>;
			mediatek,smi = <&smi_common>;
			mediatek,larb-id = <4>;
			clocks = <&imgsys CLK_IMAGE_LARB4_SMI>,
				 <&imgsys CLK_IMAGE_LARB4_SMI>;
			clock-names = "apb", "smi";
			power-domains = <&spm MT6589_POWER_DOMAIN_DIS>; /* maybe */
		};
	};
};

&pio {
	mmc0_pins_default: mmc0default {
/*
		pins-cmd-dat {
			pinmux = <MT6589_GPIO10__FUNC_MSDC0_DAT0>,
				 <MT6589_GPIO9__FUNC_MSDC0_DAT1>,
				 <MT6589_GPIO8__FUNC_MSDC0_DAT2>,
				 <MT6589_GPIO7__FUNC_MSDC0_DAT3>,
				 <MT6589_GPIO3__FUNC_MSDC0_DAT4>,
				 <MT6589_GPIO2__FUNC_MSDC0_DAT5>,
				 <MT6589_GPIO1__FUNC_MSDC0_DAT6>,
				 <MT6589_GPIO0__FUNC_MSDC0_DAT7>,
				 <MT6589_GPIO5__FUNC_MSDC0_CMD>;
			input-enable;
			drive-strength = <6>;
			// bias-pull-up = <MTK_PUPD_SET_R1R0_10>;
		};

		pins-clk {
			pinmux = <MT6589_GPIO6__FUNC_MSDC0_CLK>;
			drive-strength = <6>;
			mediatek,pull-up-adv = <2>;
		};
*/
		pins-rst {
			pinmux = <MT6589_GPIO4__FUNC_MSDC0_RSTB>;
			bias-pull-up;
		};
	};

	mmc0_pins_uhs: mmc0 {
		pins-cmd-dat {
			pinmux = <MT6589_GPIO10__FUNC_MSDC0_DAT0>,
				 <MT6589_GPIO9__FUNC_MSDC0_DAT1>,
				 <MT6589_GPIO8__FUNC_MSDC0_DAT2>,
				 <MT6589_GPIO7__FUNC_MSDC0_DAT3>,
				 <MT6589_GPIO3__FUNC_MSDC0_DAT4>,
				 <MT6589_GPIO2__FUNC_MSDC0_DAT5>,
				 <MT6589_GPIO1__FUNC_MSDC0_DAT6>,
				 <MT6589_GPIO0__FUNC_MSDC0_DAT7>,
				 <MT6589_GPIO5__FUNC_MSDC0_CMD>;
			input-enable;
			drive-strength = <6>;
			// bias-pull-up;
		};

		pins-clk {
			pinmux = <MT6589_GPIO6__FUNC_MSDC0_CLK>;
			drive-strength = <6>;
			mediatek,pull-up-adv = <2>;
		};

		pins-rst {
			pinmux = <MT6589_GPIO4__FUNC_MSDC0_RSTB>;
		};
	};

	mmc1_pins_default: mmc1default {
		pins-cmd-dat {
			pinmux = <MT6589_GPIO180__FUNC_MSDC1_DAT0>,
				 <MT6589_GPIO181__FUNC_MSDC1_DAT1>,
				 <MT6589_GPIO185__FUNC_MSDC1_DAT2>,
				 <MT6589_GPIO186__FUNC_MSDC1_DAT3>,
				 <MT6589_GPIO183__FUNC_MSDC1_CMD>;
			input-enable;
			drive-strength = <4>;
			bias-pull-up;
		};

		pins-clk {
			pinmux = <MT6589_GPIO184__FUNC_MSDC1_CLK>;
			bias-pull-down;
			drive-strength = <4>;
		};

		pins-wp {
			pinmux = <MT6589_GPIO182__FUNC_MSDC1_SDWPI>;
			input-enable;
			bias-pull-up;
		};

		pins-insert {
			pinmux = <MT6589_GPIO171__FUNC_MSDC1_INSI>;
			bias-pull-up;
		};
	};

	mmc1_pins_uhs: mmc1 {
		pins-cmd-dat {
			pinmux = <MT6589_GPIO180__FUNC_MSDC1_DAT0>,
				 <MT6589_GPIO181__FUNC_MSDC1_DAT1>,
				 <MT6589_GPIO185__FUNC_MSDC1_DAT2>,
				 <MT6589_GPIO186__FUNC_MSDC1_DAT3>,
				 <MT6589_GPIO183__FUNC_MSDC1_CMD>;
			input-enable;
			drive-strength = <8>;
			mediatek,pull-up-adv = <2>;
		};

		pins-clk {
			pinmux = <MT6589_GPIO184__FUNC_MSDC1_CLK>;
			drive-strength = <8>;
			mediatek,pull-down-adv = <2>;
		};
	};

	mmc2_pins_default: mmc2default {
		pins-cmd-dat {
			pinmux = <MT6589_GPIO179__FUNC_MSDC2_DAT0>,
				 <MT6589_GPIO178__FUNC_MSDC2_DAT1>,
				 <MT6589_GPIO174__FUNC_MSDC2_DAT2>,
				 <MT6589_GPIO175__FUNC_MSDC2_DAT3>,
				 <MT6589_GPIO176__FUNC_MSDC2_CMD>;
			input-enable;
			drive-strength = <4>;
		};

		pins-clk {
			pinmux = <MT6589_GPIO177__FUNC_MSDC2_CLK>;
			bias-pull-down;
			drive-strength = <4>;
		};

		pins-wp {
			pinmux = <MT6589_GPIO173__FUNC_MSDC2_SDWPI>;
			input-enable;
			bias-pull-up;
		};

		pins-insert {
			pinmux = <MT6589_GPIO172__FUNC_GPIO172>;
			bias-pull-up;
		};
	};

	mmc2_pins_uhs: mmc2 {
		pins-cmd-dat {
			pinmux = <MT6589_GPIO179__FUNC_MSDC2_DAT0>,
				 <MT6589_GPIO178__FUNC_MSDC2_DAT1>,
				 <MT6589_GPIO174__FUNC_MSDC2_DAT2>,
				 <MT6589_GPIO175__FUNC_MSDC2_DAT3>,
				 <MT6589_GPIO176__FUNC_MSDC2_CMD>;
			input-enable;
			drive-strength = <4>;
		};

		pins-clk {
			pinmux = <MT6589_GPIO177__FUNC_MSDC2_CLK>;
			drive-strength = <4>;
		};
	};

	mmc3_pins_default: mmc3default {
		pins-cmd-dat {
			pinmux = <MT6589_GPIO231__FUNC_MSDC3_DAT0>,
				 <MT6589_GPIO230__FUNC_MSDC3_DAT1>,
				 <MT6589_GPIO226__FUNC_MSDC3_DAT2>,
				 <MT6589_GPIO227__FUNC_MSDC3_DAT3>,
				 <MT6589_GPIO228__FUNC_MSDC3_CMD>;
			input-enable;
			drive-strength = <4>;
			mediatek,pull-up-adv = <2>;
		};

		pins-clk {
			pinmux = <MT6589_GPIO229__FUNC_MSDC3_CLK>;
			mediatek,pull-up-adv = <2>;
			drive-strength = <4>;
		};
	};

	mmc3_pins_uhs: mmc3 {
		pins-cmd-dat {
			pinmux = <MT6589_GPIO231__FUNC_MSDC3_DAT0>,
				 <MT6589_GPIO230__FUNC_MSDC3_DAT1>,
				 <MT6589_GPIO226__FUNC_MSDC3_DAT2>,
				 <MT6589_GPIO227__FUNC_MSDC3_DAT3>,
				 <MT6589_GPIO228__FUNC_MSDC3_CMD>;
			input-enable;
			drive-strength = <4>;
		};

		pins-clk {
			pinmux = <MT6589_GPIO229__FUNC_MSDC3_CLK>;
			drive-strength = <4>;
		};
	};

	mmc4_pins_default: mmc4default {
		pins-cmd-dat {
			pinmux = <MT6589_GPIO130__FUNC_MSDC4_DAT0>,
				 <MT6589_GPIO131__FUNC_MSDC4_DAT1>,
				 <MT6589_GPIO138__FUNC_MSDC4_DAT2>,
				 <MT6589_GPIO140__FUNC_MSDC4_DAT3>,
				 <MT6589_GPIO137__FUNC_MSDC4_DAT4>,
				 <MT6589_GPIO134__FUNC_MSDC4_DAT5>,
				 <MT6589_GPIO135__FUNC_MSDC4_DAT6>,
				 <MT6589_GPIO136__FUNC_MSDC4_DAT7>,
				 <MT6589_GPIO141__FUNC_MSDC4_CMD>;
			input-enable;
			mediatek,pull-up-adv = <2>;
		};

		pins-clk {
			pinmux = <MT6589_GPIO139__FUNC_MSDC4_CLK>;
			mediatek,pull-down-adv = <2>;
		};

		pins-rst {
			pinmux = <MT6589_GPIO142__FUNC_MSDC4_RSTB>;
			bias-pull-up;
		};
	};

	mmc4_pins_uhs: mmc4 {
		pins-cmd-dat {
			pinmux = <MT6589_GPIO130__FUNC_MSDC4_DAT0>,
				 <MT6589_GPIO131__FUNC_MSDC4_DAT1>,
				 <MT6589_GPIO138__FUNC_MSDC4_DAT2>,
				 <MT6589_GPIO140__FUNC_MSDC4_DAT3>,
				 <MT6589_GPIO137__FUNC_MSDC4_DAT4>,
				 <MT6589_GPIO134__FUNC_MSDC4_DAT5>,
				 <MT6589_GPIO135__FUNC_MSDC4_DAT6>,
				 <MT6589_GPIO136__FUNC_MSDC4_DAT7>,
				 <MT6589_GPIO141__FUNC_MSDC4_CMD>;
			input-enable;
			drive-strength = <2>;
		};

		pins-clk {
			pinmux = <MT6589_GPIO139__FUNC_MSDC4_CLK>;
			drive-strength = <2>;
			bias-pull-down;
		};

		pins-rst {
			pinmux = <MT6589_GPIO142__FUNC_MSDC4_RSTB>;
			bias-pull-up;
		};
	};

	i2c0_pins: i2c0-default {
		pins-i2c0 {
			pinmux = <MT6589_GPIO118__FUNC_SDA0>,
				 <MT6589_GPIO119__FUNC_SCL0>;
			bias-pull-up;
		};
	};

	i2c1_pins: i2c1-default {
		pin-i2c1 {
			pinmux = <MT6589_GPIO214__FUNC_SDA1>,
				 <MT6589_GPIO215__FUNC_SCL1>;
			bias-pull-up;
		};
	};

	i2c2_pins: i2c2-default {
		pin-i2c2 {
			pinmux = <MT6589_GPIO216__FUNC_SDA2>,
				 <MT6589_GPIO217__FUNC_SCL2>;
			bias-pull-up;
		};
	};

	i2c3_pins: i2c3-default {
		pin-i2c3 {
			pinmux = <MT6589_GPIO67__FUNC_SDA3>,
				 <MT6589_GPIO68__FUNC_SCL3>;
			bias-pull-up;
		};
	};
};
